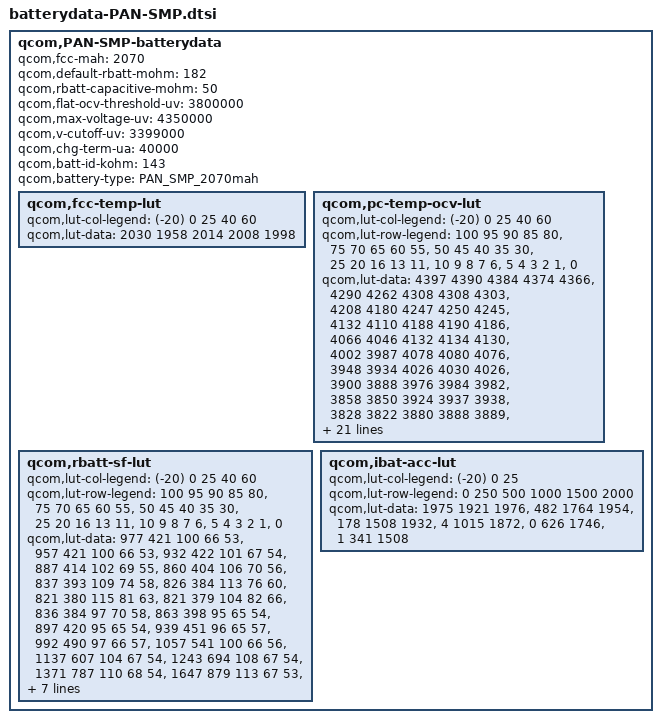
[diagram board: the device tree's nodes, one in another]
/* Copyright (c) 2013-2014, The Linux Foundation. All rights reserved.
 *
 * This program is free software; you can redistribute it and/or modify
 * it under the terms of the GNU General Public License version 2 and
 * only version 2 as published by the Free Software Foundation.
 *
 * This program is distributed in the hope that it will be useful,
 * but WITHOUT ANY WARRANTY; without even the implied warranty of
 * MERCHANTABILITY or FITNESS FOR A PARTICULAR PURPOSE.  See the
 * GNU General Public License for more details.
 */


qcom,PAN-SMP-batterydata {


	qcom,fcc-mah = <2070>;
	qcom,default-rbatt-mohm = <182>;
	qcom,rbatt-capacitive-mohm = <50>;
	qcom,flat-ocv-threshold-uv = <3800000>;
	qcom,max-voltage-uv = <4350000>;
	qcom,v-cutoff-uv = <3399000>;
	qcom,chg-term-ua = <40000>;
	qcom,batt-id-kohm = <143>;
	qcom,battery-type = "PAN_SMP_2070mah";

	qcom,fcc-temp-lut {
		qcom,lut-col-legend = <(-20) 0 25 40 60>;
		qcom,lut-data = <2030 1958 2014 2008 1998>;
	};

	qcom,pc-temp-ocv-lut {
		qcom,lut-col-legend = <(-20) 0 25 40 60>;
		qcom,lut-row-legend = <100 95 90 85 80>,
				<75 70 65 60 55>,
				<50 45 40 35 30>,
				<25 20 16 13 11>,
				<10 9 8 7 6>,
				<5 4 3 2 1>,
				<0>;
		qcom,lut-data = 
						<4397	4390	4384	4374	4366>,
						<4290	4262	4308	4308	4303>,
						<4208	4180	4247	4250	4245>,
						<4132	4110	4188	4190	4186>,
						<4066	4046	4132	4134	4130>,
						<4002	3987	4078	4080	4076>,
						<3948	3934	4026	4030	4026>,
						<3900	3888	3976	3984	3982>,
						<3858	3850	3924	3937	3938>,
						<3828	3822	3880	3888	3889>,
						<3804	3800	3846	3852	3852>,
						<3784	3784	3819	3824	3826>,
						<3764	3768	3796	3802	3804>,
						<3746	3752	3778	3784	3784>,
						<3728	3734	3764	3767	3764>,
						<3710	3716	3749	3750	3741>,
						<3688	3695	3727	3728	3716>,
						<3666	3676	3700	3702	3691>,
						<3644	3657	3679	3680	3668>,
						<3626	3643	3672	3674	3666>,
						<3613	3632	3668	3672	3664>,
						<3600	3621	3664	3671	3662>,
						<3587	3610	3661	3668	3661>,
						<3569	3594	3655	3665	3656>,
						<3545	3576	3644	3654	3638>,
						<3516	3554	3618	3626	3598>,
						<3478	3524	3574	3576	3542>,
						<3424	3478	3508	3505	3468>,
						<3344	3410	3414	3407	3363>,
						<3226	3289	3266	3258	3212>,
						<3000	3000	3000	3000	3000>;
	};

	qcom,rbatt-sf-lut {
		qcom,lut-col-legend = <(-20) 0 25 40 60>;
		qcom,lut-row-legend = <100 95 90 85 80>,
				<75 70 65 60 55>,
				<50 45 40 35 30>,
				<25 20 16 13 11>,
				<10 9 8 7 6>,
				<5 4 3 2 1>,
				<0>;
		qcom,lut-data =
						<977	421		100		66	53>,
						<957	421		100		66	53>,
						<932	422		101		67	54>,
						<887	414		102		69	55>,
						<860	404		106		70	56>,
						<837	393		109		74	58>,
						<826	384		113		76	60>,
						<821	380		115		81	63>,
						<821	379		104		82	66>,
						<836	384		97		70	58>,
						<863	398		95		65	54>,
						<897	420		95		65	54>,
						<939	451		96		65	57>,
						<992	490		97		66	57>,
						<1057	541		100		66	56>,
						<1137	607		104		67	54>,
						<1243	694		108		67	54>,
						<1371	787		110		68	54>,
						<1647	879		113		67	53>,
						<1988	947		119		69	56>,
						<2225	990		124		71	57>,
						<2423	1035	131		74	59>,
						<2596	1080	138		77	60>,
						<3218	1153	146		79	62>,
						<4184	1236	156		81	58>,
						<5758	1352	163		78	57>,
						<8449	1667	170		77	59>,
						<13671	2250	188		81	62>,
						<25269	3372	226		89	75>,
						<50537	6290	452		178	149>,
						<101074	12580	904		356	298>;
	};


	qcom,ibat-acc-lut {
		qcom,lut-col-legend = <(-20) 0 25>;
		qcom,lut-row-legend = <0 250 500 1000 1500 2000>;
		qcom,lut-data = 
						<1975	1921	1976>,
						<482	1764	1954>,
						<178	1508	1932>,
						<4		1015	1872>,
						<0		626		1746>,
						<1		341		1508>;	
	};


};
